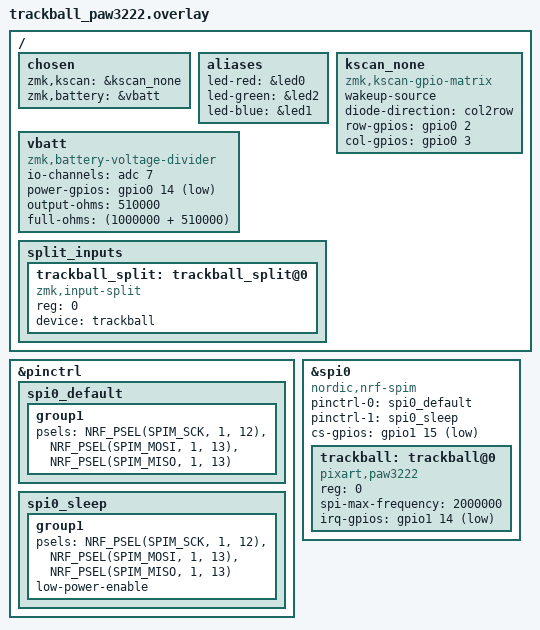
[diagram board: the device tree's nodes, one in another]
/ {
    chosen {
        zmk,kscan = &kscan_none;
        zmk,battery = &vbatt;
    };

    aliases {
        led-red = &led0;
        led-green = &led2;
        led-blue = &led1;
    };

    kscan_none: kscan_none {
        compatible = "zmk,kscan-gpio-matrix";
        wakeup-source;
        diode-direction = "col2row";
        // Dummy matrix (no actual keys) - using unused GPIOs
        row-gpios = <&gpio0 2 GPIO_ACTIVE_HIGH>;
        col-gpios = <&gpio0 3 GPIO_ACTIVE_HIGH>;
    };

    // Battery voltage divider (Xiao BLE has VBAT on P0.31)
    // Values from official ZMK seeeduino_xiao_ble.overlay
    vbatt: vbatt {
        compatible = "zmk,battery-voltage-divider";
        io-channels = <&adc 7>;
        power-gpios = <&gpio0 14 (GPIO_OPEN_DRAIN | GPIO_ACTIVE_LOW)>;
        output-ohms = <510000>;
        full-ohms = <(1000000 + 510000)>;
    };
};

&pinctrl {
    spi0_default: spi0_default {
        group1 {
            psels = <NRF_PSEL(SPIM_SCK, 1, 12)>,   // D7 = P1.12 (SCLK) ← 修正！
                    <NRF_PSEL(SPIM_MOSI, 1, 13)>,  // D8 = P1.13 (SDIO)
                    <NRF_PSEL(SPIM_MISO, 1, 13)>;  // D8 = P1.13 (SDIO - same as MOSI)
        };
    };

    spi0_sleep: spi0_sleep {
        group1 {
            psels = <NRF_PSEL(SPIM_SCK, 1, 12)>,   // ← 修正！
                    <NRF_PSEL(SPIM_MOSI, 1, 13)>,
                    <NRF_PSEL(SPIM_MISO, 1, 13)>;
            low-power-enable;
        };
    };
};

&spi0 {
    status = "okay";
    compatible = "nordic,nrf-spim";
    pinctrl-0 = <&spi0_default>;
    pinctrl-1 = <&spi0_sleep>;
    pinctrl-names = "default", "sleep";
    cs-gpios = <&gpio1 15 GPIO_ACTIVE_LOW>;  // D10 = P1.15 (CS)

    trackball: trackball@0 {
        status = "okay";
        compatible = "pixart,paw3222";
        reg = <0>;
        spi-max-frequency = <2000000>;
        irq-gpios = <&gpio1 14 (GPIO_ACTIVE_LOW | GPIO_PULL_UP)>;  // D9 = P1.14 (MOTION) ← GPIO_PULL_UP追加！

        // Note: PAW3222 driver doesn't support scroll-layers property yet
        // Scroll functionality needs to be implemented at input-processor level
    };
};

// Split input configuration (peripheral side)
/ {
    split_inputs {
        #address-cells = <1>;
        #size-cells = <0>;

        trackball_split: trackball_split@0 {
            compatible = "zmk,input-split";
            reg = <0>;
            device = <&trackball>;
        };
    };
};
